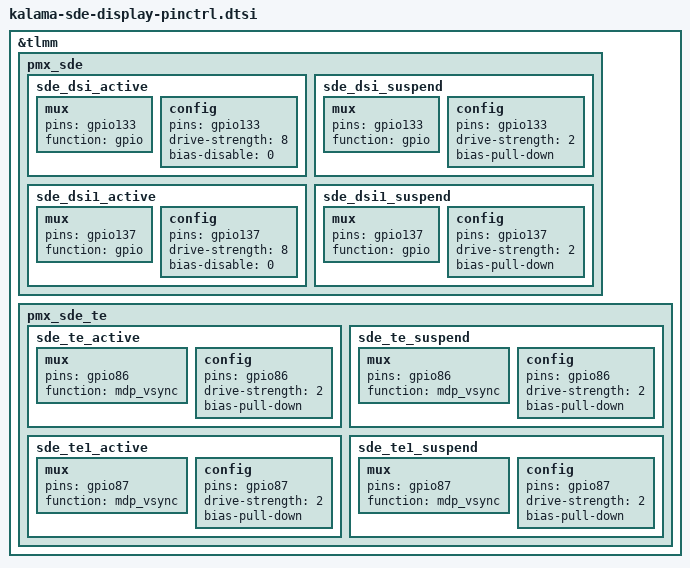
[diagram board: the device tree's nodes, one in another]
&tlmm {
	pmx_sde: pmx_sde {
		sde_dsi_active: sde_dsi_active {
			mux {
				pins = "gpio133";
				function = "gpio";
			};

			config {
				pins = "gpio133";
				drive-strength = <8>;   /* 8 mA */
				bias-disable = <0>;   /* no pull */
			};
		};

		sde_dsi_suspend: sde_dsi_suspend {
			mux {
				pins = "gpio133";
				function = "gpio";
			};

			config {
				pins = "gpio133";
				drive-strength = <2>;   /* 2 mA */
				bias-pull-down;         /* PULL DOWN */
			};
		};

		sde_dsi1_active: sde_dsi1_active {
			mux {
				pins = "gpio137";
				function = "gpio";
			};

			config {
				pins = "gpio137";
				drive-strength = <8>;   /* 8 mA */
				bias-disable = <0>;   /* no pull */
			};
		};

		sde_dsi1_suspend: sde_dsi1_suspend {
			mux {
				pins = "gpio137";
				function = "gpio";
			};

			config {
				pins = "gpio137";
				drive-strength = <2>;   /* 2 mA */
				bias-pull-down;         /* PULL DOWN */
			};
		};
	};

	pmx_sde_te: pmx_sde_te {
		sde_te_active: sde_te_active {
			mux {
				pins = "gpio86";
				function = "mdp_vsync";
			};

			config {
				pins = "gpio86";
				drive-strength = <2>;   /* 2 mA */
				bias-pull-down;         /* PULL DOWN */
			};
		};

		sde_te_suspend: sde_te_suspend {
			mux {
				pins = "gpio86";
				function = "mdp_vsync";
			};

			config {
				pins = "gpio86";
				drive-strength = <2>;   /* 2 mA */
				bias-pull-down;         /* PULL DOWN */
			};
		};

		sde_te1_active: sde_te1_active {
			mux {
				pins = "gpio87";
				function = "mdp_vsync";
			};

			config {
				pins = "gpio87";
				drive-strength = <2>;   /* 2 mA */
				bias-pull-down;         /* PULL DOWN */
			};
		};

		sde_te1_suspend: sde_te1_suspend {
			mux {
				pins = "gpio87";
				function = "mdp_vsync";
			};

			config {
				pins = "gpio87";
				drive-strength = <2>;   /* 2 mA */
				bias-pull-down;         /* PULL DOWN */
			};
		};
	};
};

